# Espressif register map
File version: 1.0
CPU: Xtensa LX6 1, little endian, no MPU, FPU, 3 interrupt priority bits
Registers are 32-bit, access not given, reset 0x0 unless marked. A register's access mark holds for its fields unless they carry their own. Offsets are from the block's base; [hi:lo] are bit positions; {n}, {i} and the like mark numbered series.

## UHCI0
Base 0x3FF54000
Same registers: UHCI1 0x3FF4C000
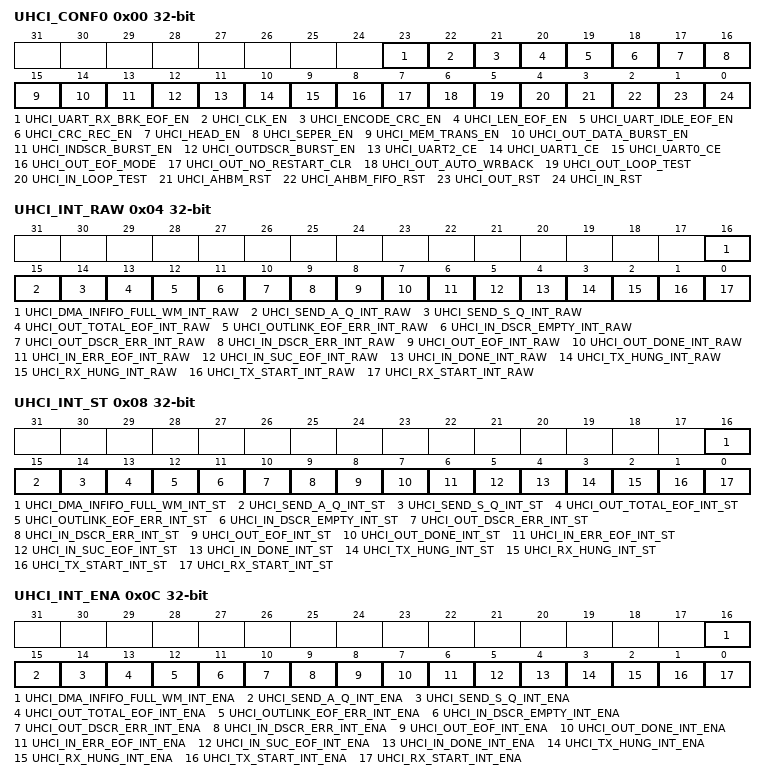
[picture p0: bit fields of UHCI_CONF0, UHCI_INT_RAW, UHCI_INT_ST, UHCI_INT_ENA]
0x00 UHCI_CONF0
  [23] UHCI_UART_RX_BRK_EOF_EN, [22] UHCI_CLK_EN, [21] UHCI_ENCODE_CRC_EN, [20] UHCI_LEN_EOF_EN, [19] UHCI_UART_IDLE_EOF_EN, [18] UHCI_CRC_REC_EN, [17] UHCI_HEAD_EN, [16] UHCI_SEPER_EN, [15] UHCI_MEM_TRANS_EN, [14] UHCI_OUT_DATA_BURST_EN, [13] UHCI_INDSCR_BURST_EN, [12] UHCI_OUTDSCR_BURST_EN, [11] UHCI_UART2_CE, [10] UHCI_UART1_CE, [9] UHCI_UART0_CE, [8] UHCI_OUT_EOF_MODE, [7] UHCI_OUT_NO_RESTART_CLR, [6] UHCI_OUT_AUTO_WRBACK, [5] UHCI_OUT_LOOP_TEST, [4] UHCI_IN_LOOP_TEST, [3] UHCI_AHBM_RST, [2] UHCI_AHBM_FIFO_RST, [1] UHCI_OUT_RST, [0] UHCI_IN_RST
0x04 UHCI_INT_RAW
  [16] UHCI_DMA_INFIFO_FULL_WM_INT_RAW, [15] UHCI_SEND_A_Q_INT_RAW, [14] UHCI_SEND_S_Q_INT_RAW, [13] UHCI_OUT_TOTAL_EOF_INT_RAW, [12] UHCI_OUTLINK_EOF_ERR_INT_RAW, [11] UHCI_IN_DSCR_EMPTY_INT_RAW, [10] UHCI_OUT_DSCR_ERR_INT_RAW, [9] UHCI_IN_DSCR_ERR_INT_RAW, [8] UHCI_OUT_EOF_INT_RAW, [7] UHCI_OUT_DONE_INT_RAW, [6] UHCI_IN_ERR_EOF_INT_RAW, [5] UHCI_IN_SUC_EOF_INT_RAW, [4] UHCI_IN_DONE_INT_RAW, [3] UHCI_TX_HUNG_INT_RAW, [2] UHCI_RX_HUNG_INT_RAW, [1] UHCI_TX_START_INT_RAW, [0] UHCI_RX_START_INT_RAW
0x08 UHCI_INT_ST
  [16] UHCI_DMA_INFIFO_FULL_WM_INT_ST, [15] UHCI_SEND_A_Q_INT_ST, [14] UHCI_SEND_S_Q_INT_ST, [13] UHCI_OUT_TOTAL_EOF_INT_ST, [12] UHCI_OUTLINK_EOF_ERR_INT_ST, [11] UHCI_IN_DSCR_EMPTY_INT_ST, [10] UHCI_OUT_DSCR_ERR_INT_ST, [9] UHCI_IN_DSCR_ERR_INT_ST, [8] UHCI_OUT_EOF_INT_ST, [7] UHCI_OUT_DONE_INT_ST, [6] UHCI_IN_ERR_EOF_INT_ST, [5] UHCI_IN_SUC_EOF_INT_ST, [4] UHCI_IN_DONE_INT_ST, [3] UHCI_TX_HUNG_INT_ST, [2] UHCI_RX_HUNG_INT_ST, [1] UHCI_TX_START_INT_ST, [0] UHCI_RX_START_INT_ST
0x0C UHCI_INT_ENA
  [16] UHCI_DMA_INFIFO_FULL_WM_INT_ENA, [15] UHCI_SEND_A_Q_INT_ENA, [14] UHCI_SEND_S_Q_INT_ENA, [13] UHCI_OUT_TOTAL_EOF_INT_ENA, [12] UHCI_OUTLINK_EOF_ERR_INT_ENA, [11] UHCI_IN_DSCR_EMPTY_INT_ENA, [10] UHCI_OUT_DSCR_ERR_INT_ENA, [9] UHCI_IN_DSCR_ERR_INT_ENA, [8] UHCI_OUT_EOF_INT_ENA, [7] UHCI_OUT_DONE_INT_ENA, [6] UHCI_IN_ERR_EOF_INT_ENA, [5] UHCI_IN_SUC_EOF_INT_ENA, [4] UHCI_IN_DONE_INT_ENA, [3] UHCI_TX_HUNG_INT_ENA, [2] UHCI_RX_HUNG_INT_ENA, [1] UHCI_TX_START_INT_ENA, [0] UHCI_RX_START_INT_ENA
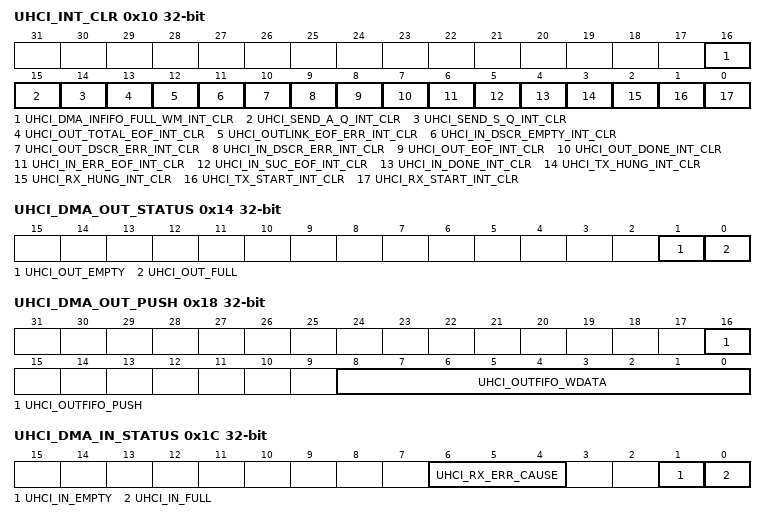
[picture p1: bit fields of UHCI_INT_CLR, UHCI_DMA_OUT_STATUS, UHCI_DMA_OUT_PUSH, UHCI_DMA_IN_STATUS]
0x10 UHCI_INT_CLR
  [16] UHCI_DMA_INFIFO_FULL_WM_INT_CLR, [15] UHCI_SEND_A_Q_INT_CLR, [14] UHCI_SEND_S_Q_INT_CLR, [13] UHCI_OUT_TOTAL_EOF_INT_CLR, [12] UHCI_OUTLINK_EOF_ERR_INT_CLR, [11] UHCI_IN_DSCR_EMPTY_INT_CLR, [10] UHCI_OUT_DSCR_ERR_INT_CLR, [9] UHCI_IN_DSCR_ERR_INT_CLR, [8] UHCI_OUT_EOF_INT_CLR, [7] UHCI_OUT_DONE_INT_CLR, [6] UHCI_IN_ERR_EOF_INT_CLR, [5] UHCI_IN_SUC_EOF_INT_CLR, [4] UHCI_IN_DONE_INT_CLR, [3] UHCI_TX_HUNG_INT_CLR, [2] UHCI_RX_HUNG_INT_CLR, [1] UHCI_TX_START_INT_CLR, [0] UHCI_RX_START_INT_CLR
0x14 UHCI_DMA_OUT_STATUS
  [1] UHCI_OUT_EMPTY, [0] UHCI_OUT_FULL
0x18 UHCI_DMA_OUT_PUSH
  [16] UHCI_OUTFIFO_PUSH, [8:0] UHCI_OUTFIFO_WDATA
0x1C UHCI_DMA_IN_STATUS
  [6:4] UHCI_RX_ERR_CAUSE, [1] UHCI_IN_EMPTY, [0] UHCI_IN_FULL
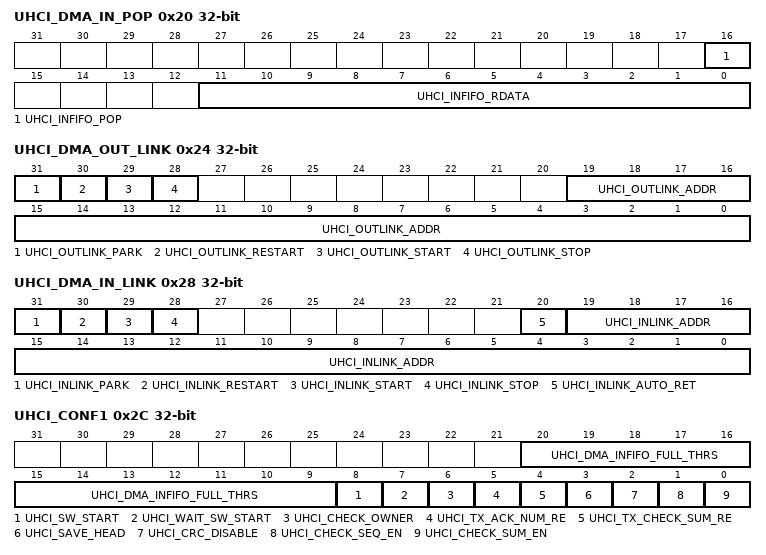
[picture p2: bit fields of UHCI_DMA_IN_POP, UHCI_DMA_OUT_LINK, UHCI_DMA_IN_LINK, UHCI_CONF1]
0x20 UHCI_DMA_IN_POP
  [16] UHCI_INFIFO_POP, [11:0] UHCI_INFIFO_RDATA
0x24 UHCI_DMA_OUT_LINK
  [31] UHCI_OUTLINK_PARK, [30] UHCI_OUTLINK_RESTART, [29] UHCI_OUTLINK_START, [28] UHCI_OUTLINK_STOP, [19:0] UHCI_OUTLINK_ADDR
0x28 UHCI_DMA_IN_LINK
  [31] UHCI_INLINK_PARK, [30] UHCI_INLINK_RESTART, [29] UHCI_INLINK_START, [28] UHCI_INLINK_STOP, [20] UHCI_INLINK_AUTO_RET, [19:0] UHCI_INLINK_ADDR
0x2C UHCI_CONF1
  [20:9] UHCI_DMA_INFIFO_FULL_THRS, [8] UHCI_SW_START, [7] UHCI_WAIT_SW_START, [6] UHCI_CHECK_OWNER, [5] UHCI_TX_ACK_NUM_RE, [4] UHCI_TX_CHECK_SUM_RE, [3] UHCI_SAVE_HEAD, [2] UHCI_CRC_DISABLE, [1] UHCI_CHECK_SEQ_EN, [0] UHCI_CHECK_SUM_EN
0x30 UHCI_STATE0
0x34 UHCI_STATE1
0x38 UHCI_DMA_OUT_EOF_DES_ADDR
  [31:0] UHCI_OUT_EOF_DES_ADDR
0x3C UHCI_DMA_IN_SUC_EOF_DES_ADDR
  [31:0] UHCI_IN_SUC_EOF_DES_ADDR
0x40 UHCI_DMA_IN_ERR_EOF_DES_ADDR
  [31:0] UHCI_IN_ERR_EOF_DES_ADDR
0x44 UHCI_DMA_OUT_EOF_BFR_DES_ADDR
  [31:0] UHCI_OUT_EOF_BFR_DES_ADDR
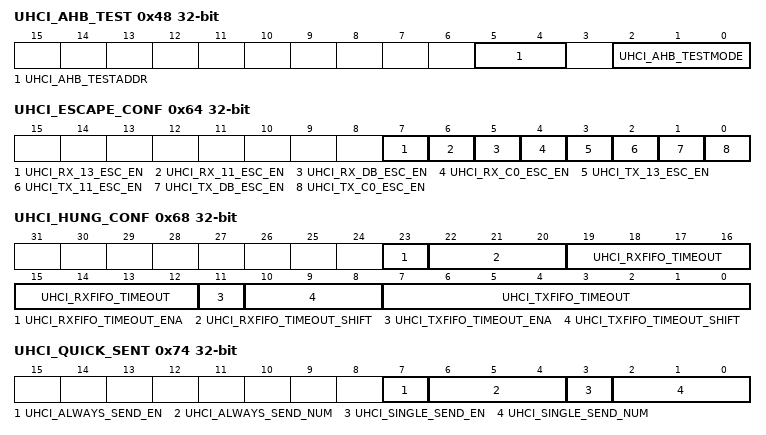
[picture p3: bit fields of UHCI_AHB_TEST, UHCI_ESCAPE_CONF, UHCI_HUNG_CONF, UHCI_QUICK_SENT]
0x48 UHCI_AHB_TEST
  [5:4] UHCI_AHB_TESTADDR, [2:0] UHCI_AHB_TESTMODE
0x4C UHCI_DMA_IN_DSCR
  [31:0] UHCI_INLINK_DSCR
0x50 UHCI_DMA_IN_DSCR_BF0
  [31:0] UHCI_INLINK_DSCR_BF0
0x54 UHCI_DMA_IN_DSCR_BF1
  [31:0] UHCI_INLINK_DSCR_BF1
0x58 UHCI_DMA_OUT_DSCR
  [31:0] UHCI_OUTLINK_DSCR
0x5C UHCI_DMA_OUT_DSCR_BF0
  [31:0] UHCI_OUTLINK_DSCR_BF0
0x60 UHCI_DMA_OUT_DSCR_BF1
  [31:0] UHCI_OUTLINK_DSCR_BF1
0x64 UHCI_ESCAPE_CONF
  [7] UHCI_RX_13_ESC_EN, [6] UHCI_RX_11_ESC_EN, [5] UHCI_RX_DB_ESC_EN, [4] UHCI_RX_C0_ESC_EN, [3] UHCI_TX_13_ESC_EN, [2] UHCI_TX_11_ESC_EN, [1] UHCI_TX_DB_ESC_EN, [0] UHCI_TX_C0_ESC_EN
0x68 UHCI_HUNG_CONF
  [23] UHCI_RXFIFO_TIMEOUT_ENA, [22:20] UHCI_RXFIFO_TIMEOUT_SHIFT, [19:12] UHCI_RXFIFO_TIMEOUT, [11] UHCI_TXFIFO_TIMEOUT_ENA, [10:8] UHCI_TXFIFO_TIMEOUT_SHIFT, [7:0] UHCI_TXFIFO_TIMEOUT
0x70 UHCI_RX_HEAD
0x74 UHCI_QUICK_SENT
  [7] UHCI_ALWAYS_SEND_EN, [6:4] UHCI_ALWAYS_SEND_NUM, [3] UHCI_SINGLE_SEND_EN, [2:0] UHCI_SINGLE_SEND_NUM
{0x78+8i} UHCI_Q{i}_WORD0 (i=0..6)
  [31:0] UHCI_SEND_Q{i}_WORD0
{0x7C+8i} UHCI_Q{i}_WORD1 (i=0..6)
  [31:0] UHCI_SEND_Q{i}_WORD1
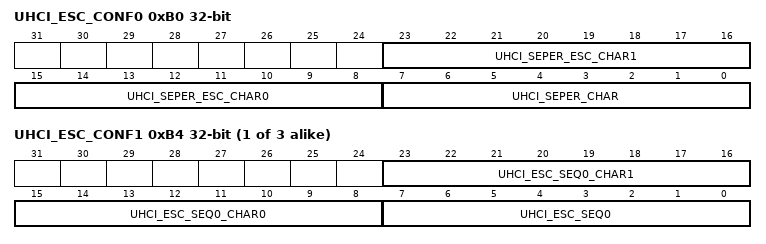
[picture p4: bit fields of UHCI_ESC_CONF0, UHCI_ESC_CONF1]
0xB0 UHCI_ESC_CONF0
  [23:16] UHCI_SEPER_ESC_CHAR1, [15:8] UHCI_SEPER_ESC_CHAR0, [7:0] UHCI_SEPER_CHAR
{0xB0+4i} UHCI_ESC_CONF{i} (i=1..3)
  [23:16] UHCI_ESC_SEQ{i-1}_CHAR1, [15:8] UHCI_ESC_SEQ{i-1}_CHAR0, [7:0] UHCI_ESC_SEQ{i-1}
0xC0 UHCI_PKT_THRES
  [12:0] UHCI_PKT_THRS
0xFC UHCI_DATE
